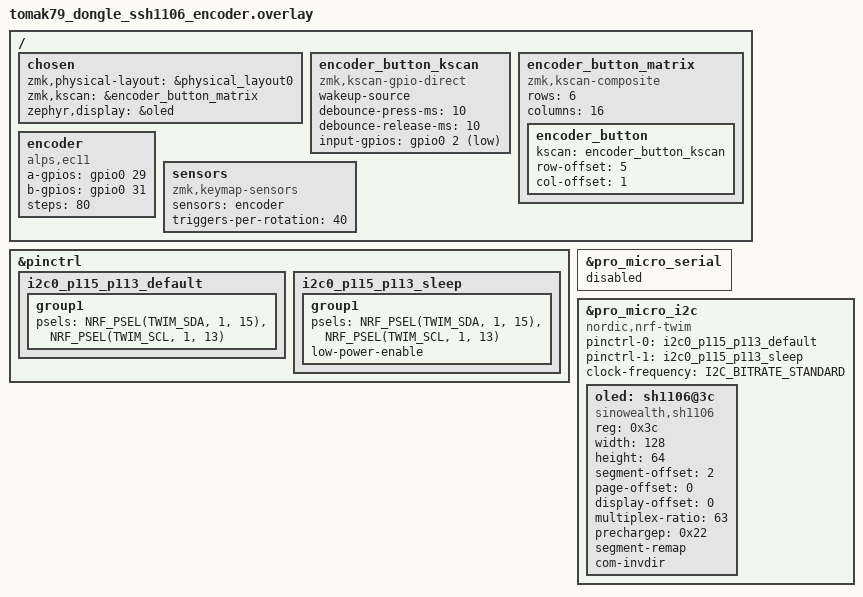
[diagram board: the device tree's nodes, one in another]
#include <behaviors.dtsi>
#include <dt-bindings/i2c/i2c.h>
#include <dt-bindings/zmk/keys.h>
#include "tomak79.dtsi"

/ {
    chosen {
        zmk,physical-layout = &physical_layout0;
        zmk,kscan = &encoder_button_matrix;
        zephyr,display = &oled;
    };

    encoder_button_kscan: encoder_button_kscan {
        compatible = "zmk,kscan-gpio-direct";
        wakeup-source;
        debounce-press-ms = <10>;
        debounce-release-ms = <10>;
        input-gpios = <&gpio0 2 (GPIO_ACTIVE_LOW | GPIO_PULL_UP)>;
    };

    encoder_button_matrix: encoder_button_matrix {
        compatible = "zmk,kscan-composite";
        rows = <6>;
        columns = <16>;

        encoder_button {
            kscan = <&encoder_button_kscan>;
            row-offset = <5>;
            col-offset = <1>;
        };
    };

    encoder: encoder {
        compatible = "alps,ec11";
        a-gpios = <&gpio0 29 (GPIO_ACTIVE_HIGH | GPIO_PULL_UP)>;
        b-gpios = <&gpio0 31 (GPIO_ACTIVE_HIGH | GPIO_PULL_UP)>;
        steps = <80>;
        status = "okay";
    };

    sensors: sensors {
        compatible = "zmk,keymap-sensors";
        sensors = <&encoder>;
        triggers-per-rotation = <40>;
    };
};

&pinctrl {
    i2c0_p115_p113_default: i2c0_p115_p113_default {
        group1 {
            psels = <NRF_PSEL(TWIM_SDA, 1, 15)>,
                <NRF_PSEL(TWIM_SCL, 1, 13)>;
        };
    };

    i2c0_p115_p113_sleep: i2c0_p115_p113_sleep {
        group1 {
            psels = <NRF_PSEL(TWIM_SDA, 1, 15)>,
                <NRF_PSEL(TWIM_SCL, 1, 13)>;
            low-power-enable;
        };
    };
};

&pro_micro_serial {
    status = "disabled";
};

&pro_micro_i2c {
    compatible = "nordic,nrf-twim";
    status = "okay";
    pinctrl-0 = <&i2c0_p115_p113_default>;
    pinctrl-1 = <&i2c0_p115_p113_sleep>;
    pinctrl-names = "default", "sleep";
    clock-frequency = <I2C_BITRATE_STANDARD>;

    oled: sh1106@3c {
        compatible = "sinowealth,sh1106";
        reg = <0x3c>;
        width = <128>;
        height = <64>;
        segment-offset = <2>;
        page-offset = <0>;
        display-offset = <0>;
        multiplex-ratio = <63>;
        prechargep = <0x22>;
        segment-remap;
        com-invdir;
    };
};
